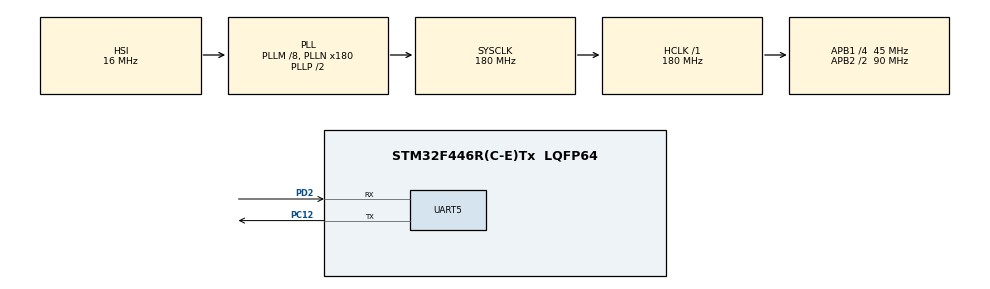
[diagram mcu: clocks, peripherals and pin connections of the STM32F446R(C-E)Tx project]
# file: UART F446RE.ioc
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Mcu.Family=STM32F4
Mcu.Name=STM32F446R(C-E)Tx
Mcu.Package=LQFP64
NVIC.PriorityGroup=NVIC_PRIORITYGROUP_4
NVIC.RCC_IRQn=true\:0\:0\:false\:false\:true\:true\:false\:true
NVIC.UART5_IRQn=true\:0\:0\:false\:false\:true\:true\:true\:true
PA13.Mode=Serial_Wire
PA13.Signal=SYS_JTMS-SWDIO
PA14.Mode=Serial_Wire
PA14.Signal=SYS_JTCK-SWCLK
PC12.Mode=Asynchronous
PC12.Signal=UART5_TX
PC14-OSC32_IN.Mode=LSE-External-Oscillator
PC14-OSC32_IN.Signal=RCC_OSC32_IN
PC15-OSC32_OUT.Mode=LSE-External-Oscillator
PC15-OSC32_OUT.Signal=RCC_OSC32_OUT
PD2.Mode=Asynchronous
PD2.Signal=UART5_RX
PH0-OSC_IN.Mode=HSE-External-Oscillator
PH0-OSC_IN.Signal=RCC_OSC_IN
PH1-OSC_OUT.Mode=HSE-External-Oscillator
PH1-OSC_OUT.Signal=RCC_OSC_OUT
ProjectManager.HeapSize=0x200
ProjectManager.StackSize=0x400
ProjectManager.TargetToolchain=STM32CubeIDE
RCC.AHBFreq_Value=180000000
RCC.APB1CLKDivider=RCC_HCLK_DIV4
RCC.APB1Freq_Value=45000000
RCC.APB1TimFreq_Value=90000000
RCC.APB2CLKDivider=RCC_HCLK_DIV2
RCC.APB2Freq_Value=90000000
RCC.APB2TimFreq_Value=180000000
RCC.CortexFreq_Value=180000000
RCC.HCLKFreq_Value=180000000
RCC.PLLM=8
RCC.PLLN=180
RCC.SYSCLKFreq_VALUE=180000000
RCC.SYSCLKSource=RCC_SYSCLKSOURCE_PLLCLK
RCC.USBFreq_Value=180000000
RCC.VCOOutputFreq_Value=360000000
UART5.VirtualMode=Asynchronous
board=custom

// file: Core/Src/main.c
/* USER CODE BEGIN Header */
/**
  ******************************************************************************
  * @file           : main.c
  * @brief          : Main program body
  ******************************************************************************
  * @attention
  *
  * Copyright (c) 2023 STMicroelectronics.
  * All rights reserved.
  *
  * This software is licensed under terms that can be found in the LICENSE file
  * in the root directory of this software component.
  * If no LICENSE file comes with this software, it is provided AS-IS.
  *
  ******************************************************************************
  */
/* USER CODE END Header */
#include "main.h"

/* USER CODE BEGIN Includes */
#include "string.h"
/* USER CODE END Includes */

UART_HandleTypeDef huart5;

/* USER CODE BEGIN PV */
char tempbuf[]="Hello Duta'h\r\n";

/* USER CODE END PV */

void SystemClock_Config(void);
static void MX_GPIO_Init(void);
static void MX_UART5_Init(void);

int main(void)
{

  /* MCU Configuration--------------------------------------------------------*/

  /* Reset of all peripherals, Initializes the Flash interface and the Systick. */
  HAL_Init();

  /* Configure the system clock */
  SystemClock_Config();

  /* Initialize all configured peripherals */
  MX_GPIO_Init();
  MX_UART5_Init();
  /* USER CODE BEGIN 2 */
//  HAL_UART_Transmit_DMA(&huart2, tempbuf, strlen(tempbuf));
  /* USER CODE END 2 */

  /* Infinite loop */
  /* USER CODE BEGIN WHILE */
  while (1)
  {
	  HAL_UART_Transmit(&huart5, tempbuf, strlen(tempbuf), 100);
	  //HAL_Delay(1000);
    /* USER CODE END WHILE */

  }
}

void SystemClock_Config(void)
{
  RCC_OscInitTypeDef RCC_OscInitStruct = {0};
  RCC_ClkInitTypeDef RCC_ClkInitStruct = {0};

  /** Configure the main internal regulator output voltage
  */
  __HAL_RCC_PWR_CLK_ENABLE();
  __HAL_PWR_VOLTAGESCALING_CONFIG(PWR_REGULATOR_VOLTAGE_SCALE1);

  /** Initializes the RCC Oscillators according to the specified parameters
  * in the RCC_OscInitTypeDef structure.
  */
  RCC_OscInitStruct.OscillatorType = RCC_OSCILLATORTYPE_HSI;
  RCC_OscInitStruct.HSIState = RCC_HSI_ON;
  RCC_OscInitStruct.HSICalibrationValue = RCC_HSICALIBRATION_DEFAULT;
  RCC_OscInitStruct.PLL.PLLState = RCC_PLL_ON;
  RCC_OscInitStruct.PLL.PLLSource = RCC_PLLSOURCE_HSI;
  RCC_OscInitStruct.PLL.PLLM = 8;
  RCC_OscInitStruct.PLL.PLLN = 180;
  RCC_OscInitStruct.PLL.PLLP = RCC_PLLP_DIV2;
  RCC_OscInitStruct.PLL.PLLQ = 2;
  RCC_OscInitStruct.PLL.PLLR = 2;
  if (HAL_RCC_OscConfig(&RCC_OscInitStruct) != HAL_OK)
  {
    Error_Handler();
  }

  /** Activate the Over-Drive mode
  */
  if (HAL_PWREx_EnableOverDrive() != HAL_OK)
  {
    Error_Handler();
  }

  /** Initializes the CPU, AHB and APB buses clocks
  */
  RCC_ClkInitStruct.ClockType = RCC_CLOCKTYPE_HCLK|RCC_CLOCKTYPE_SYSCLK
                              |RCC_CLOCKTYPE_PCLK1|RCC_CLOCKTYPE_PCLK2;
  RCC_ClkInitStruct.SYSCLKSource = RCC_SYSCLKSOURCE_PLLCLK;
  RCC_ClkInitStruct.AHBCLKDivider = RCC_SYSCLK_DIV1;
  RCC_ClkInitStruct.APB1CLKDivider = RCC_HCLK_DIV4;
  RCC_ClkInitStruct.APB2CLKDivider = RCC_HCLK_DIV2;

  if (HAL_RCC_ClockConfig(&RCC_ClkInitStruct, FLASH_LATENCY_5) != HAL_OK)
  {
    Error_Handler();
  }
}

static void MX_UART5_Init(void)
{

  huart5.Instance = UART5;
  huart5.Init.BaudRate = 115200;
  huart5.Init.WordLength = UART_WORDLENGTH_8B;
  huart5.Init.StopBits = UART_STOPBITS_1;
  huart5.Init.Parity = UART_PARITY_NONE;
  huart5.Init.Mode = UART_MODE_TX_RX;
  huart5.Init.HwFlowCtl = UART_HWCONTROL_NONE;
  huart5.Init.OverSampling = UART_OVERSAMPLING_16;
  if (HAL_UART_Init(&huart5) != HAL_OK)
  {
    Error_Handler();
  }

}

static void MX_GPIO_Init(void)
{

  /* GPIO Ports Clock Enable */
  __HAL_RCC_GPIOC_CLK_ENABLE();
  __HAL_RCC_GPIOH_CLK_ENABLE();
  __HAL_RCC_GPIOA_CLK_ENABLE();
  __HAL_RCC_GPIOD_CLK_ENABLE();

}

/* USER CODE BEGIN 4 */
int _write(int file, char *ptr, int len)
{
	int DataIdx;

	for (DataIdx = 0; DataIdx < len; DataIdx++)
	{
		ITM_SendChar(*ptr++);
	}
	return len;
}
/* USER CODE END 4 */

void Error_Handler(void)
{
  __disable_irq();
  while (1)
  {
  }
}
